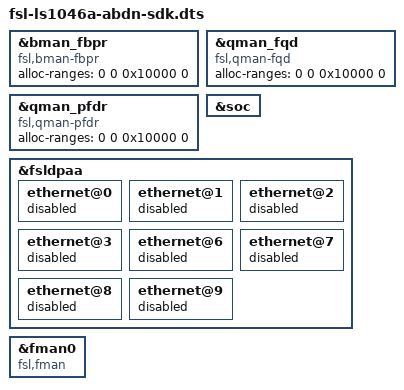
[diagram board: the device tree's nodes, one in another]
// SPDX-License-Identifier: (GPL-2.0+ OR MIT)
/*
 * Device Tree file for Layerscape LS1046A based Aberdeen board
 *
 * Copyright 2019 NXP
 *
 */

#include "fsl-ls1046a-abdn.dts"
#include "qoriq-qman-portals-sdk.dtsi"
#include "qoriq-bman-portals-sdk.dtsi"

&bman_fbpr {
	compatible = "fsl,bman-fbpr";
	alloc-ranges = <0 0 0x10000 0>;
};
&qman_fqd {
	compatible = "fsl,qman-fqd";
	alloc-ranges = <0 0 0x10000 0>;
};
&qman_pfdr {
	compatible = "fsl,qman-pfdr";
	alloc-ranges = <0 0 0x10000 0>;
};

&soc {
#include "qoriq-dpaa-eth.dtsi"
#include "qoriq-fman3-0-6oh.dtsi"
};

&fsldpaa {
	ethernet@0 {
		status = "disabled";
	};
	ethernet@1 {
		status = "disabled";
	};
	ethernet@2 {
		status = "disabled";
	};
	ethernet@3 {
		status = "disabled";
	};
	ethernet@6 {
		status = "disabled";
	};
	ethernet@7 {
		status = "disabled";
	};
	ethernet@8 {
		status = "disabled";
	};
	ethernet@9 {
		status = "disabled";
	};
};

&fman0 {
	compatible = "fsl,fman", "simple-bus";
};
